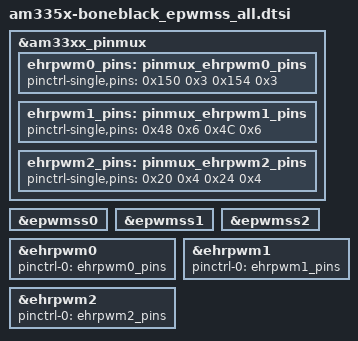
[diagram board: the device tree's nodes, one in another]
/*
 * Copyright (C) 2012 Texas Instruments Incorporated - http://www.ti.com/
 *
 * This program is free software; you can redistribute it and/or modify
 * it under the terms of the GNU General Public License version 2 as
 * published by the Free Software Foundation.
 */

/include/ "am33xx.dtsi"

/include/ "am335x-bone-common.dtsi"

&am33xx_pinmux {
        ehrpwm0_pins: pinmux_ehrpwm0_pins {
                pinctrl-single,pins = <
                        0x150 0x3       /* spi0_sclk.ehrpwm0A , OUTPUT_PULLDOWN | MODE3 P9_22*/
                        0x154 0x3       /* spi0_d0  .ehrpwm0B , OUTPUT_PULLDOWN | MODE3 P9_21*/
                >;
        };
        ehrpwm1_pins: pinmux_ehrpwm1_pins {
                pinctrl-single,pins = <
                        0x48 0x6       /* gpmc_a2.ehrpwm1A , OUTPUT_PULLDOWN | MODE3 P9_14*/
                        0x4C 0x6       /* gpmc_a3.ehrpwm1B , OUTPUT_PULLDOWN | MODE3 P9_16*/
                >;
        };
        ehrpwm2_pins: pinmux_ehrpwm2_pins {
                pinctrl-single,pins = <
                        0x20 0x4       /* gpmc_ad8.ehrpwm2A , OUTPUT_PULLDOWN | MODE3 P8_19*/
                        0x24 0x4       /* gpmc_ad9.ehrpwm2B , OUTPUT_PULLDOWN | MODE3 P8_13*/
                >;
        };
};

&epwmss0 {
        status = "okay";
};
&epwmss1 {
        status = "okay";
};
&epwmss2 {
        status = "okay";
};


&ehrpwm0 {
        status = "okay";
        pinctrl-names = "default";
        pinctrl-0 = <&ehrpwm0_pins>;
};

&ehrpwm1 {
        status = "okay";
        pinctrl-names = "default";
        pinctrl-0 = <&ehrpwm1_pins>;
};

&ehrpwm2 {
        status = "okay";
        pinctrl-names = "default";
        pinctrl-0 = <&ehrpwm2_pins>;
};


